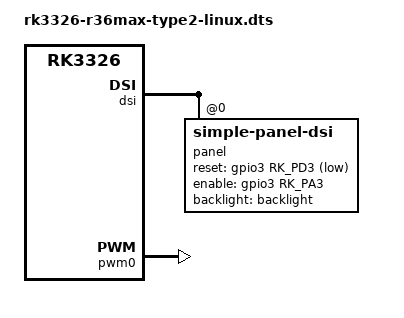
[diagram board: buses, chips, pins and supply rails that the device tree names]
// SPDX-License-Identifier: (GPL-2.0+ OR MIT)
/*
* Copyright (c) 2025 kk&lcdyk
*
* 稀范科技 R36Max Type2
*
*/

/dts-v1/;
#include "rk3326-r36max-type1-linux.dts"

&backlight {
	compatible = "pwm-backlight";
	pwms = <&pwm0 0 25000 0>;
	brightness-levels = <
	0   1   2   3   4   5   6   7
	8   9  10  11  12  13  14  15
	16  17  18  19  20  21  22  23
	24  25  26  27  28  29  30  31
	32  33  34  35  36  37  38  39
	40  41  42  43  44  45  46  47
	48  49  50  51  52  53  54  55
	56  57  58  59  60  61  62  63
	64  65  66  67  68  69  70  71
	72  73  74  75  76  77  78  79
	80  81  82  83  84  85  86  87
	88  89  90  91  92  93  94  95
	96  97  98  99 100 101 102 103
	104 105 106 107 108 109 110 111
	112 113 114 115 116 117 118 119
	120 121 122 123 124 125 126 127
	128 129 130 131 132 133 134 135
	136 137 138 139 140 141 142 143
	144 145 146 147 148 149 150 151
	152 153 154 155 156 157 158 159
	160 161 162 163 164 165 166 167
	168 169 170 171 172 173 174 175
	176 177 178 179 180 181 182 183
	184 185 186 187 188 189 190 191
	192 193 194 195 196 197 198 199
	200 201 202 203 204 205 206 207
	208 209 210 211 212 213 214 215
	216 217 218 219 220 221 222 223
	224 225 226 227 228 229 230 231
	232 233 234 235 236 237 238 239
	240 241 242 243 244 245 246 247
	248 249 250 251 252 253 254 255>;
	default-brightness-level = <200>;
};

&dsi {
	status = "okay";
	
	panel@0 {
		compatible = "simple-panel-dsi";
		reg = <0>;
		/* pwm1 backlight */
		backlight = <&backlight>;
		/* LCD reset gpio GPIO3.B7 */
		reset-gpios = <&gpio3 RK_PD3 GPIO_ACTIVE_LOW>;
		/* LCD reset gpio GPIO0.B5 */
		enable-gpios = <&gpio3 RK_PA3 GPIO_ACTIVE_HIGH>;
		prepare-delay-ms = <120>;
		reset-delay-ms = <120>;
		init-delay-ms = <120>;
		enable-delay-ms = <120>;
		disable-delay-ms = <120>;
		unprepare-delay-ms = <120>;
		width-mm = <153>;
		height-mm = <85>;
		dsi,flags  = <(MIPI_DSI_MODE_VIDEO |
		MIPI_DSI_MODE_VIDEO_BURST |
		MIPI_DSI_MODE_LPM |
		MIPI_DSI_MODE_EOT_PACKET)>;
		dsi,format = <MIPI_DSI_FMT_RGB888>;
		dsi,lanes = <4>;
		panel-init-sequence = [39 00 04 b9 f1 12 83 39 00 06 b1 00 00 00 da 80 39 00 04 b2 3c 12 30 39 00 0b b3 10 10 28 28 03 ff 00 00 00 00 15 00 02 b4 80 39 00 03 b5 0a 0a 39 00 03 b6 97 97 39 00 05 b8 26 22 f0 13 39 00 1c ba 33 81 05 f9 0e 0e 20 00 00 00 00 00 00 00 44 25 00 90 0a 00 00 01 4f 01 00 00 37 15 00 02 bc 47 39 00 04 bf 02 11 00 39 00 0a c0 73 73 50 50 00 00 12 70 00 39 00 0d c1 25 00 32 32 77 e4 ff ff cc cc 77 77 39 00 07 c6 82 00 bf ff 00 ff 39 00 07 c7 b8 00 0a 00 00 00 39 00 05 c8 10 40 1e 02 15 00 02 cc 0b 39 00 23 e0 00 0b 10 2c 3d 3f 42 3a 07 0d 0f 13 15 13 14 0f 16 00 0b 10 2c 3d 3f 42 3a 07 0d 0f 13 15 13 14 0f 16 39 00 0f e3 07 07 0b 0b 0b 0b 00 00 00 00 ff 00 c0 10 39 00 40 e9 c8 10 0a 00 00 80 81 12 31 23 4f 86 a0 00 47 08 00 00 0c 00 00 00 00 00 0c 00 00 00 98 02 8b af 46 02 88 88 88 88 88 98 13 8b af 57 13 88 88 88 88 88 00 00 00 00 00 00 00 00 00 00 00 00 00 39 00 3e ea 97 0c 09 09 09 78 00 00 00 00 00 00 9f 31 8b a8 31 75 88 88 88 88 88 9f 20 8b a8 20 64 88 88 88 88 88 23 00 00 02 71 00 00 00 00 00 00 00 00 00 00 00 00 00 00 00 40 80 81 00 00 00 00 39 00 04 ef ff ff 01 05 fa 01 11 05 32 01 29];
		panel-exit-sequence = <0x5000128 0x5000110>;
		
		display-timings {
			native-mode = <&timing0>;
			
			// 50.00MHz / (720+140+80+140)×(720+20+4+20) = 1080×764 = 60.60 Hz
			timing0: original {
				clock-frequency = <50000000>;
				hactive = <720>;
				vactive = <720>;
				hfront-porch = <140>;
				hsync-len = <80>;
				hback-porch = <140>;
				vfront-porch = <20>;
				vsync-len = <4>;
				vback-porch = <20>;
				hsync-active = <0>;
				vsync-active = <0>;
				de-active = <0>;
				pixelclk-active = <0>;
			};
			
			// 50.00MHz / (720+143+80+142)×(720+22+4+22) = 1085×768 = 60.00 Hz
			timing1: adjust {
				clock-frequency = <50000000>;
				hactive = <720>;
				vactive = <720>;
				hfront-porch = <143>;
				hsync-len = <80>;
				hback-porch = <142>;
				vfront-porch = <22>;
				vsync-len = <4>;
				vback-porch = <22>;
				hsync-active = <0>;
				vsync-active = <0>;
				de-active = <0>;
				pixelclk-active = <0>;
			};
		};
	};
};

&pwm0 {
	status = "okay";
};

&rk817_codec {
    /delete-property/ spk-ctl-gpios;
    /delete-property/ spk-mute-delay-ms;
    /delete-property/ use-ext-amplifier;
};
